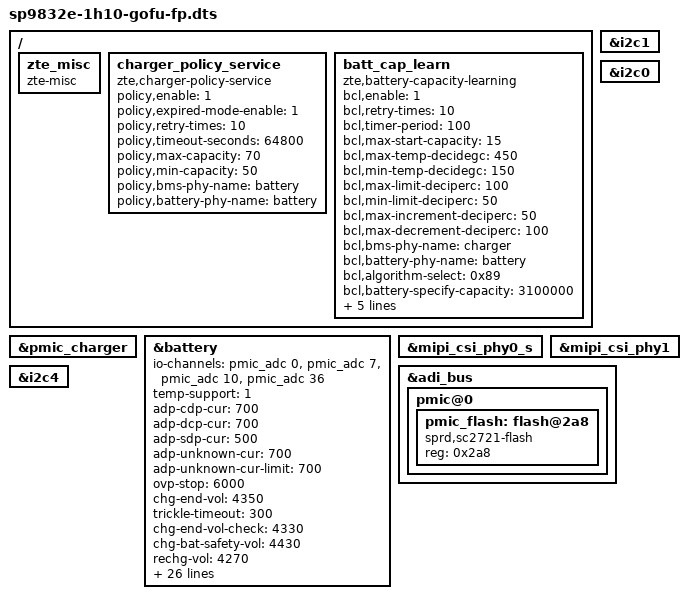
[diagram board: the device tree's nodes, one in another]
/*****************************************
Do not modify dts file, please modify according dtsi file
******************************************/

#include "../sp9832e-1h10-gofu-fp.dts"
#include "sprd_base_diff.dtsi"

/ {
	zte_misc: zte_misc {
		status = "okay";
		compatible = "zte-misc";
	};

	charger_policy_service {
		compatible = "zte,charger-policy-service";
		status="okay";
		policy,enable = <1>;
		policy,expired-mode-enable = <1>;
		policy,retry-times = <10>;
		policy,timeout-seconds = <64800>;/* 18 hours */
		policy,max-capacity = <70>;
		policy,min-capacity = <50>;
		policy,bms-phy-name = "battery";
		policy,battery-phy-name = "battery";
	};

	batt_cap_learn {
		compatible = "zte,battery-capacity-learning";
		bcl,enable = <1>;
		bcl,retry-times = <10>;
		bcl,timer-period = <100>;/*ms*/
		bcl,max-start-capacity = <15>;
		bcl,max-temp-decidegc = <450>;
		bcl,min-temp-decidegc = <150>;
		bcl,max-limit-deciperc = <100>;
		bcl,min-limit-deciperc = <50>;
		bcl,max-increment-deciperc = <50>;
		bcl,max-decrement-deciperc = <100>;
		bcl,bms-phy-name = "charger";
		bcl,battery-phy-name = "battery";
		/*bit7: 0: use zte algorithm calc age; 1: use platform algorithm calc age*/
		/*bit4: enable zte algorithm*/
		/*bit3: enable platform algorithm*/
		/*bit0: platform algorithm mode 0: integral mode; 1: delta mode*/
		bcl,algorithm-select = <0x89>;
		bcl,battery-specify-capacity = <3100000>;
		bcl,battery-specify-voltage = <4390>;

		/*3.4V-3.0V 0.2C delta capacity*/
		/*age 150ma 768ma(0.2C) 1300ma*/
		bcl,disch-curr-volt-prop = <100 64 193 393
						86 82 258 412>;

		/*current: 0.04C - 0.02C delta*/
		bcl,topoff-prop = <100 50
				86 72 >;

		/*reduc voltage  50mv 100mv*/
		bcl,reduc-volt-prop = <100 193 366
					86 230 396 >;
	};
};

&pmic_charger {
	status = "okay";
};

&battery {
	io-channels = <&pmic_adc 0>,<&pmic_adc 7>,<&pmic_adc 10>,
			<&pmic_adc 36>;
	io-channel-names = "adc_batt_id","adc_temp","adc_vbat",
			"adc_vchg";
	temp-support = <1>;
	adp-cdp-cur = <700>;
	adp-dcp-cur = <700>;
	adp-sdp-cur = <500>;
	adp-unknown-cur = <700>;
	adp-unknown-cur-limit = <700>;
	ovp-stop = <6000>;
	chg-end-vol = <4350>;
	trickle-timeout = <300>;
	chg-end-vol-check = <4330>;
	chg-bat-safety-vol = <4430>;
	rechg-vol = <4270>;
	chg-polling-time = <25>;
	chg-polling-time-fast = <5>;
	rsense-real = <100>;
	soft-vbat-uvlo = <3250>;
	bat-id-list = <47 270>; /* battery id kohm fenghua:47K weike:270K */
	rint = <203>;
	cnom = <1840>;
	ocv-tab-vol = <4345 4275 4215 4160 4108 4065 4007
			3973 3931 3885 3852 3828 3810 3795
			3782 3767 3749 3726 3698 3683 3500>;
	rint-1 = <203>;
	cnom-1 = <1840>;
	ocv-tab-vol-1 = <4345 4275 4215 4160 4108 4065 4007
			3973 3931 3885 3852 3828 3810 3795
			3782 3767 3749 3726 3698 3683 3500>;
	ocv-tab-cap = <100  95   90   85   80   75   70
			65   60   55   50   45   40   35
			30   25   20   15   10   5    0>;
	/*30mohm,if temp-table-mode = <1>, use it*/
	temp-comp-res = <30>;
	temp-tab-val = <1160 1150 1138 1122 1102 1078
			1048 1013 971 925 873 816
			756 694 632 570 510 453 401>;
	/* temperature + 1000,750 = 1000 + (-250)*/
	temp-tab-temp = <750 800 850 900 950 1000
			1050 1100 1150 1200 1250 1300
			1350 1400 1450 1500 1550 1600 1650>;
	jeita-temp-tab = <1000 1050 1150 1450 1550>;
	jeita-temp-recovery-tab = <1030 1080 1180 1420 1520>;
	jeita-cur-tab = <0 500 500 0x7FFF 650 0>;
	jeita-cccv-tab = <4350 4350 4350 4350 4100 4100>;
	batt_full_design_capacity = <1840>;
};

&i2c1 {
	/delete-node/ sensor-sub@20;
};

&i2c1 {
	/delete-node/ sensor-main2@6c;
};

&i2c0 {
	/delete-node/ sensor-main@20;
};

&mipi_csi_phy0_s {
	/delete-node/ port;
};

&mipi_csi_phy1 {
	/delete-node/ port;
};

&i2c4 {
	/delete-node/ flash-ic@63;
};

&adi_bus {
	pmic@0 {
		/delete-node/ flash@2a8;
	};
	pmic@0 {
		pmic_flash: flash@2a8 {
					compatible = "sprd,sc2721-flash";
					reg=<0x2a8>;
					status = "okay";
					};
		};
};



&pmic_flash {
	compatible = "sprd,sc2721-flash";
	reg=<0x2a8>;
};

